# SIM3C164_B register map
File version: 1
CPU: 
Registers are 32-bit, read-write, reset 0x0 unless marked. A register's access mark holds for its fields unless they carry their own. Offsets are from the block's base; [hi:lo] are bit positions; 'fields as' and 'values as' point back to an identical list; <NAME> marks a mode.

## PBCFG_0
Base 0x4002A000
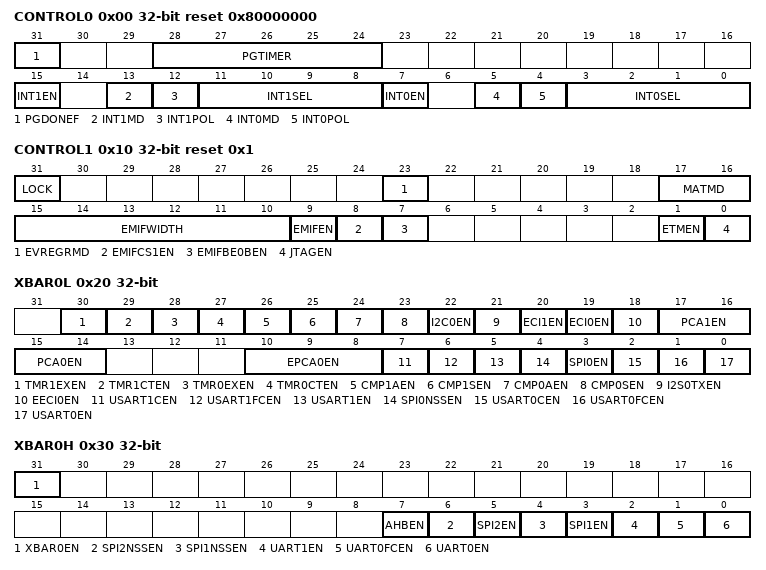
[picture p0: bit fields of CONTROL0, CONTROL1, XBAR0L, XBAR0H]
0x00 CONTROL0 reset 0x80000000 — Global Port Control 0
  [31] PGDONEF ro — Pulse Generator Timer Done Flag.
    0=NOT_SET (Firmware has written to the PBPGPHASE register, but the Pulse Generator timer has not expired.); 1=SET (The Pulse Generator cycle finished since the last time PBPGPHASE was written.)
  [28:24] PGTIMER — Pulse Generator Timer.
  [15] INT1EN — External Interrupt 1 Enable.
    0=DISABLED (Disable external interrupt 1.); 1=ENABLED (Enable external interrupt 1.)
  [13] INT1MD — External Interrupt 1 Mode.
    0=LEVEL (Interrupt based on level sensitivity.); 1=EDGE (Interrupt based on edge sensitivity.)
  [12] INT1POL — External Interrupt 1 Polarity.
    0=LOW (A low value or falling edge on the selected pin will cause interrupt.); 1=HIGH (A high value or rising edge on the selected pin will cause interrupt.)
  [11:8] INT1SEL — External Interrupt 1 Pin Selection.
    0=INT1_0 (Select INT1.0 (PB3.0)); 1=INT1_1 (Select INT1.1 (PB3.1)); 2=INT1_2 (Select INT1.2 (PB3.2)); 3=INT1_3 (Select INT1.3 (PB3.3)); 4=INT1_4 (Select INT1.4 (RESERVED)); 5=INT1_5 (Select INT1.5 (RESERVED)); 6=INT1_6 (Select INT1.6 (RESERVED)); 7=INT1_7 (Select INT1.7 (RESERVED)); 8=INT1_8 (Select INT1.8 (RESERVED)); 9=INT1_9 (Select INT1.9 (RESERVED)); 10=INT1_10 (Select INT1.10 (RESERVED)); 11=INT1_11 (Select INT1.11 (RESERVED)); 12=INT1_12 (Select INT1.12 (RESERVED)); 13=INT1_13 (Select INT1.13 (RESERVED)); 14=INT1_14 (Select INT1.14 (RESERVED)); 15=INT1_15 (Select INT1.15 (RESERVED))
  [7] INT0EN — External Interrupt 0 Enable.
    0=DISABLED (Disable external interrupt 0.); 1=ENABLED (Enable external interrupt 0.)
  [5] INT0MD — External Interrupt 0 Mode.
    values as INT1MD
  [4] INT0POL — External Interrupt 0 Polarity.
    values as INT1POL
  [3:0] INT0SEL — External Interrupt 0 Pin Selection.
    0=INT0_0 (Select INT0.0 (PB3.0)); 1=INT0_1 (Select INT0.1 (PB3.1)); 2=INT0_2 (Select INT0.2 (PB3.2)); 3=INT0_3 (Select INT0.3 (PB3.3)); 4=INT0_4 (Select INT0.4 (RESERVED)); 5=INT0_5 (Select INT0.5 (RESERVED)); 6=INT0_6 (Select INT0.6 (RESERVED)); 7=INT0_7 (Select INT0.7 (RESERVED)); 8=INT0_8 (Select INT0.8 (RESERVED)); 9=INT0_9 (Select INT0.9 (RESERVED)); 10=INT0_10 (Select INT0.10 (RESERVED)); 11=INT0_11 (Select INT0.11 (RESERVED)); 12=INT0_12 (Select INT0.12 (RESERVED)); 13=INT0_13 (Select INT0.13 (RESERVED)); 14=INT0_14 (Select INT0.14 (RESERVED)); 15=INT0_15 (Select INT0.15 (RESERVED))
0x10 CONTROL1 reset 0x1 — Global Port Control 1
  [31] LOCK — Port Bank Configuration Lock.
    0=UNLOCKED (Port Bank Configuration and Control registers are unlocked.); 1=LOCKED (The following registers are locked from write access: CONTROL1, XBAR0L, XBAR0H, XBAR1, and all PBSKIP registers.)
  [23] EVREGRMD — External Regulator Reset Mode.
    0=RESET_ON_ANY (The pins used by the external regulator will default to digital inputs with weak pull-up enabled on any reset.); 1=RESET_ON_POR (The pins used by the external regulator will default to digital inputs with weak pull-up enabled only on Power-On Reset. Their configured mode will be preserved through all other resets.)
  [17:16] MATMD — Match Mode.
    0=PINMATCH (Port Match registers used to provide interrupt / wake sources.); 1=CAPSENSE_TX (Port Match registers used to monitor output pin activity for Capacitive Sensing measurements.); 2=CAPSENSE_RX (Port Match registers used to monitor input pin activity for Capacitive Sensing measurements.)
  [15:10] EMIFWIDTH
    0=AWIDTH_8 (EMIF Address[7:0]); 1=AWIDTH_9 (EMIF Address[8:0], PB2.8 = A[8]); 2=AWIDTH_10 (EMIF Address[9:0], PB2.7 = A[9]); 3=AWIDTH_11 (EMIF Address[10:0], PB2.6 = A[10]); 4=AWIDTH_12 (EMIF Address[11:0], PB2.5 = A[11]); 5=AWIDTH_13 (EMIF Address[12:0], PB2.4 = A[12]); 6=AWIDTH_14 (EMIF Address[13:0], PB2.3 = A[13]); 7=AWIDTH_15 (EMIF Address[14:0], PB2.2 = A[14]); 8=AWIDTH_16 (EMIF Address[15:0], PB2.1 = A[15]); 9=AWIDTH_17 (EMIF Address[16:0], PB2.0 = A[16]); 10=AWIDTH_18 (EMIF Address[17:0], PB1.15 = A[17]); 11=AWIDTH_19 (EMIF Address[18:0], PB1.14 = A[18]); 12=AWIDTH_20 (EMIF Address[19:0], PB1.13 = A[19]); 13=AWIDTH_21 (EMIF Address[20:0], PB1.12 = A[20]); 14=AWIDTH_22 (EMIF Address[21:0], PB1.11 = A[21]); 15=AWIDTH_23 (EMIF Address[22:0], PB1.10 = A[22]); 16=AWIDTH_24 (EMIF Address[23:0], PB1.10 = A[23])
  [9] EMIFEN — EMIF Enable.
    0=DISABLED (Disable the EMIF pins.); 1=ENABLED (EMIF is enabled and pinned out.)
  [8] EMIFCS1EN — EMIF CS1 Pin Enable.
    0=DISABLED (Disable the EMIF CS1 pin.); 1=ENABLED (Enable the CS1 pin if EMIFEN is also set to 1.)
  [7] EMIFBE0BEN — EMIF <overline>BE0</overline> Pin Enable.
    0=DISABLED (Disable the EMIF /BE0 pin.); 1=ENABLED (Enable the /BE0 pin if EMIFEN is also set to 1.)
  [1] ETMEN — ETM Enable.
    0=DISABLED (ETM not pinned out.); 1=ENABLED (ETM is enabled and pinned out.)
  [0] JTAGEN — JTAG Enable.
    0=DISABLED (JTAG functionality is not pinned out.); 1=ENABLED (JTAG functionality is pinned out.)
0x20 XBAR0L — Crossbar 0 Control (Low)
  [30] TMR1EXEN — TIMER1 T1EX Enable.
    0=DISABLED (Disable TIMER1 EX on Crossbar 0.); 1=ENABLED (Enable TIMER1 EX on Crossbar 0.)
  [29] TMR1CTEN — TIMER1 T1CT Enable.
    0=DISABLED (Disable TIMER1 CT on Crossbar 0.); 1=ENABLED (Enable TIMER1 CT on Crossbar 0.)
  [28] TMR0EXEN — TIMER0 T0EX Enable.
    0=DISABLED (Disable TIMER0 EX on Crossbar 0.); 1=ENABLED (Enable TIMER0 EX on Crossbar 0.)
  [27] TMR0CTEN — TIMER0 T0CT Enable.
    0=DISABLED (Disable TIMER0 CT on Crossbar 0.); 1=ENABLED (Enable TIMER0 CT on Crossbar 0.)
  [26] CMP1AEN — Comparator 1 Asynchronous Output (CMP1A) Enable.
    0=DISABLED (Disable Comparator 1 Asynchronous Output (CMP1A) on Crossbar 0.); 1=ENABLED (Enable Comparator 1 Asynchronous Output (CMP1A) on Crossbar 0.)
  [25] CMP1SEN — Comparator 1 Synchronous Output (CMP1S) Enable.
    0=DISABLED (Disable Comparator 1 Synchronous Output (CMP1S) on Crossbar 0.); 1=ENABLED (Enable Comparator 1 Synchronous Output (CMP1S) on Crossbar 0.)
  [24] CMP0AEN — Comparator 0 Asynchronous Output (CMP0A) Enable.
    0=DISABLED (Disable Comparator 0 Asynchronous Output (CMP0A) on Crossbar 0.); 1=ENABLED (Enable Comparator 0 Asynchronous Output (CMP0A) on Crossbar 0.)
  [23] CMP0SEN — Comparator 0 Synchronous Output (CMP0S) Enable.
    0=DISABLED (Disable Comparator 0 Synchronous Output (CMP0S) on Crossbar 0.); 1=ENABLED (Enable Comparator 0 Synchronous Output (CMP0S) on Crossbar 0.)
  [22] I2C0EN — I2C0 Enable.
    0=DISABLED (Disable I2C0 SDA and SCL on Crossbar 0.); 1=ENABLED (Enable I2C0 SDA and SCL on Crossbar 0.)
  [21] I2S0TXEN — I2S0 TX Enable.
    0=DISABLED (Disable I2S0 TX on Crossbar 0.); 1=ENABLED (Enable I2S0 TX on Crossbar 0.)
  [20] ECI1EN — PCA1 ECI Enable.
    0=DISABLED (Disable PCA1 ECI on Crossbar 0.); 1=ENABLED (Enable PCA1 ECI on Crossbar 0.)
  [19] ECI0EN — PCA0 ECI Enable.
    0=DISABLED (Disable PCA0 ECI on Crossbar 0.); 1=ENABLED (Enable PCA0 ECI on Crossbar 0.)
  [18] EECI0EN — EPCA0 ECI Enable.
    0=DISABLED (Disable EPCA0 ECI on Crossbar 0.); 1=ENABLED (Enable EPCA0 ECI on Crossbar 0.)
  [17:16] PCA1EN — PCA1 Channel Enable.
    0=NONE (Disable all PCA1 channels on Crossbar 0.); 1=CEX0 (Enable PCA1 CEX0 on Crossbar 0.); 3=CEX0_1 (Enable PCA1 CEX0 and CEX1 on Crossbar 0.)
  [15:14] PCA0EN — PCA0 Channel Enable.
    0=NONE (Disable all PCA0 channels on Crossbar 0.); 1=CEX0 (Enable PCA0 CEX0 on Crossbar 0.); 3=CEX0_1 (Enable PCA0 CEX0 and CEX1 on Crossbar 0.)
  [10:8] EPCA0EN — EPCA0 Channel Enable.
    0=NONE (Disable all EPCA0 channels on Crossbar 0.); 1=STD_CEX0 (Enable EPCA0 STD_CEX0 on Crossbar 0.); 2=STD_CEX0_1 (Enable EPCA0 STD_CEX0 and STD_CEX1 on Crossbar 0.); 3=STD_CEX0_2 (Enable EPCA0 STD_CEX0, STD_CEX1, and STD_CEX2 on Crossbar 0.); 4=STD_CEX0_3 (Enable EPCA0 STD_CEX0, STD_CEX1, STD_CEX2, and STD_CEX3 on Crossbar 0.); 5=STD_CEX0_4 (Enable EPCA0 STD_CEX0, STD_CEX1, STD_CEX2, STD_CEX3, and STD_CEX4 on Crossbar 0.); 6=STD_CEX0_5 (Enable EPCA0 STD_CEX0, STD_CEX1, STD_CEX2, STD_CEX3, STD_CEX4, and STD_CEX5 on Crossbar 0.)
  [7] USART1CEN — USART1 Clock Signal Enable.
    0=DISABLED (Disable USART1 clock on Crossbar 0.); 1=ENABLED (Enable USART1 clock on Crossbar 0.)
  [6] USART1FCEN — USART1 Flow Control Enable.
    0=DISABLED (Disable USART1 flow control on Crossbar 0.); 1=ENABLED (Enable USART1 flow control on Crossbar 0.)
  [5] USART1EN — USART1 Enable.
    0=DISABLED (Disable USART1 RX and TX on Crossbar 0.); 1=ENABLED (Enable USART1 RX and TX on Crossbar 0.)
  [4] SPI0NSSEN — SPI0 NSS Pin Enable.
    0=DISABLED (Disable SPI0 NSS on Crossbar 0.); 1=ENABLED (Enable SPI0 NSS on Crossbar 0.)
  [3] SPI0EN — SPI0 Enable.
    0=DISABLED (Disable SPI0 SCK, MISO, and MOSI on Crossbar 0.); 1=ENABLED (Enable SPI0 SCK, MISO, and MOSI on Crossbar 0.)
  [2] USART0CEN — USART0 Clock Signal Enable.
    0=DISABLED (Disable USART0 clock on Crossbar 0.); 1=ENABLED (Enable USART0 clock on Crossbar 0.)
  [1] USART0FCEN — USART0 Flow Control Enable.
    0=DISABLED (Disable USART0 flow control on Crossbar 0.); 1=ENABLED (Enable USART0 flow control on Crossbar 0.)
  [0] USART0EN — USART0 Enable.
    0=DISABLED (Disable USART0 RX and TX on Crossbar 0.); 1=ENABLED (Enable USART0 RX and TX on Crossbar 0.)
0x30 XBAR0H — Crossbar 0 Control (High)
  [31] XBAR0EN — Crossbar 0 Enable.
    0=DISABLED (Disable Crossbar 0.); 1=ENABLED (Enable Crossbar 0.)
  [7] AHBEN — AHB Clock Output Enable.
    0=DISABLED (Disable the AHB Clock / 16 output on Crossbar 0.); 1=ENABLED (Enable the AHB Clock / 16 output on Crossbar 0.)
  [6] SPI2NSSEN — SPI2 NSS Pin Enable.
    0=DISABLED (Disable SPI2 NSS on Crossbar 0.); 1=ENABLED (Enable SPI2 NSS on Crossbar 0.)
  [5] SPI2EN — SPI2 Enable.
    0=DISABLED (Disable SPI2 SCK, MISO, and MOSI on Crossbar 0.); 1=ENABLED (Enable SPI2 SCK, MISO, and MOSI on Crossbar 0.)
  [4] SPI1NSSEN — SPI1 NSS Pin Enable.
    0=DISABLED (Disable SPI1 NSS on Crossbar 0.); 1=ENABLED (Enable SPI1 NSS on Crossbar 0.)
  [3] SPI1EN — SPI1 Enable.
    0=DISABLED (Disable SPI1 SCK, MISO, and MOSI on Crossbar 0.); 1=ENABLED (Enable SPI1 SCK, MISO, and MOSI on Crossbar 0.)
  [2] UART1EN — UART1 Enable.
    0=DISABLED (Disable UART1 RX and TX on Crossbar 0.); 1=ENABLED (Enable UART1 RX and TX on Crossbar 0.)
  [1] UART0FCEN — UART0 Flow Control Enable.
    0=DISABLED (Disable UART0 flow control on Crossbar 0.); 1=ENABLED (Enable UART0 flow control on Crossbar 0.)
  [0] UART0EN — UART0 Enable.
    0=DISABLED (Disable UART0 RX and TX on Crossbar 0.); 1=ENABLED (Enable UART0 RX and TX on Crossbar 0.)
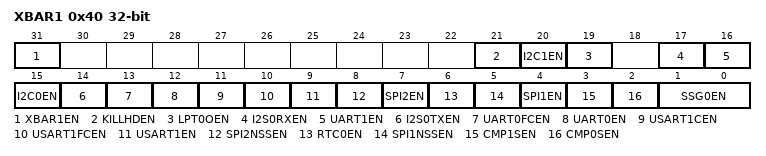
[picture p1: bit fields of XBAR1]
0x40 XBAR1 — Crossbar 1 Control
  [31] XBAR1EN — Crossbar 1 Enable.
    0=DISABLED (Disable Crossbar 1.); 1=ENABLED (Enable Crossbar 1.)
  [21] KILLHDEN — High Drive Kill Pin Enable.
    0=DISABLED (Disable the PB High Drive Kill Pin on Crossbar 1.); 1=ENABLED (Enable the PB High Drive Kill Pin on Crossbar 1.)
  [20] I2C1EN — I2C1 Enable.
    0=DISABLED (Disable I2C1 SDA and SCL on Crossbar 1.); 1=ENABLED (Enable I2C1 SDA and SCL on Crossbar 1.)
  [19] LPT0OEN — LPTIMER0 Output Enable.
    0=DISABLED (Disable LPTIMER0 Output on Crossbar 1.); 1=ENABLED (Enable LPTIMER0 Output on Crossbar 1.)
  [17] I2S0RXEN — I2S0 RX Enable.
    0=DISABLED (Disable I2S0 RX on Crossbar 1.); 1=ENABLED (Enable I2S0 RX on Crossbar 1.)
  [16] UART1EN — UART1 Enable.
    0=DISABLED (Disable UART1 RX and TX on Crossbar 1.); 1=ENABLED (Enable UART1 RX and TX on Crossbar 1.)
  [15] I2C0EN — I2C0 Enable.
    0=DISABLED (Disable I2C0 SDA and SCL on Crossbar 1.); 1=ENABLED (Enable I2C0 SDA and SCL on Crossbar 1.)
  [14] I2S0TXEN — I2S0 TX Enable.
    0=DISABLED (Disable I2S0 TX on Crossbar 1.); 1=ENABLED (Enable I2S0 TX on Crossbar 1.)
  [13] UART0FCEN — UART0 Flow Control Enable.
    0=DISABLED (Disable UART0 flow control on Crossbar 1.); 1=ENABLED (Enable UART0 flow control on Crossbar1.)
  [12] UART0EN — UART0 Enable.
    0=DISABLED (Disable UART0 RX and TX on Crossbar 1.); 1=ENABLED (Enable UART0 RX and TX on Crossbar 1.)
  [11] USART1CEN — USART1 Clock Signal Enable.
    0=DISABLED (Disable USART1 clock on Crossbar 1.); 1=ENABLED (Enable USART1 clock on Crossbar 1.)
  [10] USART1FCEN — USART1 Flow Control Enable.
    0=DISABLED (Disable USART1 flow control on Crossbar 1.); 1=ENABLED (Enable USART1 flow control on Crossbar 1.)
  [9] USART1EN — USART1 Enable.
    0=DISABLED (Disable USART1 RX and TX on Crossbar 1.); 1=ENABLED (Enable USART1 RX and TX on Crossbar 1.)
  [8] SPI2NSSEN — SPI2 NSS Pin Enable.
    0=DISABLED (Disable SPI2 NSS on Crossbar 1.); 1=ENABLED (Enable SPI2 NSS on Crossbar 1.)
  [7] SPI2EN — SPI2 Enable.
    0=DISABLED (Disable SPI2 SCK, MISO, and MOSI on Crossbar 1.); 1=ENABLED (Enable SPI2 SCK, MISO, and MOSI on Crossbar 1.)
  [6] RTC0EN — RTC0 Output Enable.
    0=DISABLED (Disable RTC0 Output on Crossbar 1.); 1=ENABLED (Enable RTC0 Output on Crossbar 1.)
  [5] SPI1NSSEN — SPI1 NSS Pin Enable.
    0=DISABLED (Disable SPI1 NSS on Crossbar 1.); 1=ENABLED (Enable SPI1 NSS on Crossbar 1.)
  [4] SPI1EN — SPI1 Enable.
    0=DISABLED (Disable SPI1 SCK, MISO, and MOSI on Crossbar 1.); 1=ENABLED (Enable SPI1 SCK, MISO, and MOSI on Crossbar 1.)
  [3] CMP1SEN — Comparator 1 Synchronous Output (CMP1S) Enable.
    0=DISABLED (Disable Comparator 1 Synchronous Output (CMP1S) on Crossbar 1.); 1=ENABLED (Enable Comparator 1 Synchronous Output (CMP1S) on Crossbar 1.)
  [2] CMP0SEN — Comparator 0 Synchronous Output (CMP0S) Enable.
    0=DISABLED (Disable Comparator 0 Synchronous Output (CMP0S) on Crossbar 1.); 1=ENABLED (Enable Comparator 0 Synchronous Output (CMP0S) on Crossbar 1.)
  [1:0] SSG0EN — SSG0 Enable.
    0=NONE (Disable all SSG0 channels on Crossbar 1.); 1=EX0 (Enable SSG0 EX0 on Crossbar 1.); 2=EX0_1 (Enable SSG0 EX0 and EX1 on Crossbar 1.); 3=EX0_3 (Enable SSG0 EX0, EX1, EX2, and EX3 on Crossbar 1.)
0x50 PBKEY — Global Port Key
  [7:0] KEY — Port Bank 2, 3, and 4 Key.
    0=LOCKED (Port Bank 2, 3, and 4 registers are locked and no valid values have been written to PBKEY.); 1=INTERMEDIATE (Port Bank 2, 3, and 4 registers are locked and the first valid value (0xA5) has been written to PBKEY.); 2=UNLOCKED (Port Bank 2, 3, and 4 registers are unlocked. Any subsequent writes to the Port Bank 2, 3, or 4 registers or PBKEY will lock the interface.)
